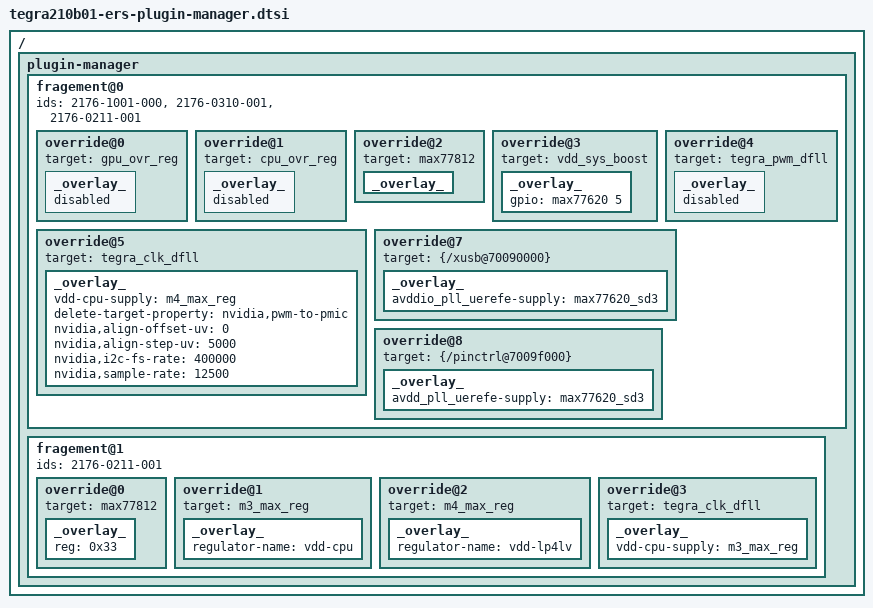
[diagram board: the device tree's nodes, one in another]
/*
 * Copyright (c) 2017, NVIDIA CORPORATION.  All rights reserved.
 *
 * This program is free software; you can redistribute it and/or modify
 * it under the terms of the GNU General Public License as published by
 * the Free Software Foundation; version 2 of the License.
 *
 * This program is distributed in the hope that it will be useful, but WITHOUT
 * ANY WARRANTY; without even the implied warranty of MERCHANTABILITY or
 * FITNESS FOR A PARTICULAR PURPOSE.  See the GNU General Public License for
 * more details.
 *
 */

/ {
	plugin-manager {
		fragement@0 {
			ids = "2176-1001-000", "2176-0310-001", "2176-0211-001";
			override@0 {
				target = <&gpu_ovr_reg>;
				_overlay_ {
					status = "disabled";
				};
			};

			override@1 {
				target = <&cpu_ovr_reg>;
				_overlay_ {
					status = "disabled";
				};
			};

			override@2 {
				target = <&max77812>;
				_overlay_ {
					status = "okay";
				};
			};

			override@3 {
				target = <&vdd_sys_boost>;
				_overlay_ {
					gpio = <&max77620 5 0>;
				};
			};

			override@4 {
				target = <&tegra_pwm_dfll>;
				_overlay_ {
					status = "disabled";
				};
			};

			override@5 {
				target = <&tegra_clk_dfll>;
				_overlay_ {
					vdd-cpu-supply = <&m4_max_reg>;
					delete-target-property = "nvidia,pwm-to-pmic";
					nvidia,align-offset-uv = <0>;
					nvidia,align-step-uv = <5000>;
					nvidia,i2c-fs-rate = <400000>;
					nvidia,sample-rate = <12500>;
				};
			};

			override@7 {
				target = <&{/xusb@70090000}>;
				_overlay_ {
					avddio_pll_uerefe-supply = <&max77620_sd3>;
				};
			};

			override@8 {
				target = <&{/pinctrl@7009f000}>;
				_overlay_ {
					avdd_pll_uerefe-supply = <&max77620_sd3>;
				};
			};
		};

		fragement@1 {
			ids = "2176-0211-001";
			override@0 {
				target = <&max77812>;
				_overlay_ {
					reg = <0x33>;
				};
			};

			override@1 {
				target = <&m3_max_reg>;
				_overlay_ {
					regulator-name = "vdd-cpu";
				};
			};

			override@2 {
				target = <&m4_max_reg>;
				_overlay_ {
					regulator-name = "vdd-lp4lv";
				};
			};

			override@3 {
				target = <&tegra_clk_dfll>;
				_overlay_ {
					vdd-cpu-supply = <&m3_max_reg>;
				};
			};
		};
	};
};
